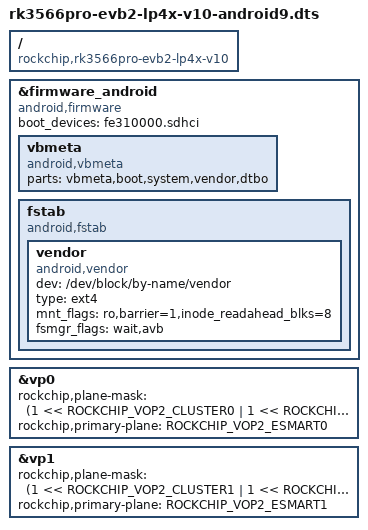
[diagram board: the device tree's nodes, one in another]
// SPDX-License-Identifier: (GPL-2.0+ OR MIT)
/*
 * Copyright (c) 2024 Rockchip Electronics Co., Ltd.
 *
 */

#include <dt-bindings/display/rockchip_vop.h>
#include "rk3566pro-evb2-lp4x-v10.dtsi"
#include "rk3568-android9.dtsi"

/ {
	compatible = "rockchip,rk3566pro-evb2-lp4x-v10", "rockchip,rk3566pro", "rockchip,rk3568";
};

&firmware_android {
	compatible = "android,firmware";
	boot_devices = "fe310000.sdhci";
	vbmeta {
		compatible = "android,vbmeta";
		parts = "vbmeta,boot,system,vendor,dtbo";
	};
	fstab {
		compatible = "android,fstab";
		vendor {
			compatible = "android,vendor";
			dev = "/dev/block/by-name/vendor";
			type = "ext4";
			mnt_flags = "ro,barrier=1,inode_readahead_blks=8";
			fsmgr_flags = "wait,avb";
		};
	};
};

/* vp0 for HDMI, vp1 for rgb */
&vp0 {
	rockchip,plane-mask = <(1 << ROCKCHIP_VOP2_CLUSTER0 | 1 << ROCKCHIP_VOP2_ESMART0 | 1 << ROCKCHIP_VOP2_SMART0)>;
	rockchip,primary-plane = <ROCKCHIP_VOP2_ESMART0>;
};

&vp1 {
	rockchip,plane-mask = <(1 << ROCKCHIP_VOP2_CLUSTER1 | 1 << ROCKCHIP_VOP2_ESMART1 | 1 << ROCKCHIP_VOP2_SMART1)>;
	rockchip,primary-plane = <ROCKCHIP_VOP2_ESMART1>;
};
